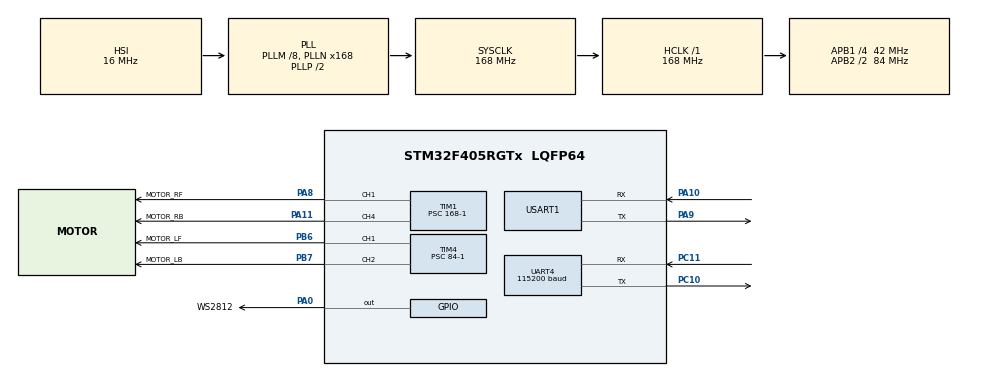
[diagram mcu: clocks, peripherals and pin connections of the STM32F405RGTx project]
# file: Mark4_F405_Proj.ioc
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Dma.Request0=USART1_RX
Dma.Request1=UART4_RX
Dma.UART4_RX.1.Direction=DMA_PERIPH_TO_MEMORY
Dma.UART4_RX.1.FIFOMode=DMA_FIFOMODE_DISABLE
Dma.UART4_RX.1.Instance=DMA1_Stream2
Dma.UART4_RX.1.MemDataAlignment=DMA_MDATAALIGN_BYTE
Dma.UART4_RX.1.MemInc=DMA_MINC_ENABLE
Dma.UART4_RX.1.Mode=DMA_NORMAL
Dma.UART4_RX.1.PeriphDataAlignment=DMA_PDATAALIGN_BYTE
Dma.UART4_RX.1.PeriphInc=DMA_PINC_DISABLE
Dma.UART4_RX.1.Priority=DMA_PRIORITY_LOW
Dma.USART1_RX.0.Direction=DMA_PERIPH_TO_MEMORY
Dma.USART1_RX.0.FIFOMode=DMA_FIFOMODE_DISABLE
Dma.USART1_RX.0.Instance=DMA2_Stream2
Dma.USART1_RX.0.MemDataAlignment=DMA_MDATAALIGN_BYTE
Dma.USART1_RX.0.MemInc=DMA_MINC_ENABLE
Dma.USART1_RX.0.Mode=DMA_NORMAL
Dma.USART1_RX.0.PeriphDataAlignment=DMA_PDATAALIGN_BYTE
Dma.USART1_RX.0.PeriphInc=DMA_PINC_DISABLE
Dma.USART1_RX.0.Priority=DMA_PRIORITY_LOW
Mcu.Family=STM32F4
Mcu.Name=STM32F405RGTx
Mcu.Package=LQFP64
NVIC.DMA1_Stream2_IRQn=true\:0\:0\:false\:false\:true\:false\:true\:true
NVIC.DMA2_Stream2_IRQn=true\:0\:0\:false\:false\:true\:false\:true\:true
NVIC.PriorityGroup=NVIC_PRIORITYGROUP_4
NVIC.TIM3_IRQn=true\:0\:0\:false\:false\:true\:true\:true\:true
NVIC.UART4_IRQn=true\:1\:0\:true\:false\:true\:true\:true\:true
NVIC.USART1_IRQn=true\:2\:0\:true\:false\:true\:true\:true\:true
PA0-WKUP.GPIO_Label=WS2812
PA0-WKUP.GPIO_Speed=GPIO_SPEED_FREQ_HIGH
PA0-WKUP.Signal=GPIO_Output
PA10.Mode=Asynchronous
PA10.Signal=USART1_RX
PA11.GPIO_Label=MOTOR_RB
PA11.Signal=S_TIM1_CH4
PA13.Mode=Serial_Wire
PA13.Signal=SYS_JTMS-SWDIO
PA14.Mode=Serial_Wire
PA14.Signal=SYS_JTCK-SWCLK
PA8.GPIO_Label=MOTOR_RF
PA8.Signal=S_TIM1_CH1
PA9.Mode=Asynchronous
PA9.Signal=USART1_TX
PB6.GPIO_Label=MOTOR_LF
PB6.Signal=S_TIM4_CH1
PB7.GPIO_Label=MOTOR_LB
PB7.Signal=S_TIM4_CH2
PC10.Mode=Asynchronous
PC10.Signal=UART4_TX
PC11.Mode=Asynchronous
PC11.Signal=UART4_RX
PH0-OSC_IN.Mode=HSE-External-Oscillator
PH0-OSC_IN.Signal=RCC_OSC_IN
PH1-OSC_OUT.Mode=HSE-External-Oscillator
PH1-OSC_OUT.Signal=RCC_OSC_OUT
ProjectManager.HeapSize=0x200
ProjectManager.StackSize=0x400
ProjectManager.TargetToolchain=CMake
RCC.48MHZClocksFreq_Value=84000000
RCC.AHBFreq_Value=168000000
RCC.APB1CLKDivider=RCC_HCLK_DIV4
RCC.APB1Freq_Value=42000000
RCC.APB1TimFreq_Value=84000000
RCC.APB2CLKDivider=RCC_HCLK_DIV2
RCC.APB2Freq_Value=84000000
RCC.APB2TimFreq_Value=168000000
RCC.CortexFreq_Value=168000000
RCC.HCLKFreq_Value=168000000
RCC.HSE_VALUE=12000000
RCC.HSI_VALUE=16000000
RCC.LSE_VALUE=32768
RCC.PLLM=8
RCC.PLLN=168
RCC.SYSCLKFreq_VALUE=168000000
RCC.SYSCLKSource=RCC_SYSCLKSOURCE_PLLCLK
RCC.VCOOutputFreq_Value=336000000
SH.S_TIM1_CH1.0=TIM1_CH1,PWM Generation1 CH1
SH.S_TIM1_CH4.0=TIM1_CH4,PWM Generation4 CH4
SH.S_TIM4_CH1.0=TIM4_CH1,PWM Generation1 CH1
SH.S_TIM4_CH2.0=TIM4_CH2,PWM Generation2 CH2
TIM1.AutoReloadPreload=TIM_AUTORELOAD_PRELOAD_ENABLE
TIM1.Channel-PWM\ Generation1\ CH1=TIM_CHANNEL_1
TIM1.Channel-PWM\ Generation4\ CH4=TIM_CHANNEL_4
TIM1.Period=20000-1
TIM1.Prescaler=168-1
TIM3.Period=9
TIM3.Prescaler=8399
TIM4.AutoReloadPreload=TIM_AUTORELOAD_PRELOAD_ENABLE
TIM4.Channel-PWM\ Generation1\ CH1=TIM_CHANNEL_1
TIM4.Channel-PWM\ Generation2\ CH2=TIM_CHANNEL_2
TIM4.Period=20000-1
TIM4.Prescaler=84-1
UART4.BaudRate=115200
UART4.VirtualMode=Asynchronous
USART1.VirtualMode=VM_ASYNC
VP_TIM1_VS_ClockSourceINT.Mode=Internal
VP_TIM3_VS_ClockSourceINT.Mode=Internal
VP_TIM4_VS_ClockSourceINT.Mode=Internal
board=custom

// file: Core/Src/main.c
/* USER CODE BEGIN Header */
/**
  ******************************************************************************
  * @file           : main.c
  * @brief          : Main program body
  ******************************************************************************
  * @attention
  *
  * Copyright (c) 2025 STMicroelectronics.
  * All rights reserved.
  *
  * This software is licensed under terms that can be found in the LICENSE file
  * in the root directory of this software component.
  * If no LICENSE file comes with this software, it is provided AS-IS.
  *
  ******************************************************************************
  */
/* USER CODE END Header */
#include "main.h"
#include "dma.h"
#include "tim.h"
#include "usart.h"
#include "gpio.h"

void SystemClock_Config(void);

int main(void)
{

  /* MCU Configuration--------------------------------------------------------*/

  /* Reset of all peripherals, Initializes the Flash interface and the Systick. */
  HAL_Init();

  /* Configure the system clock */
  SystemClock_Config();

  /* Initialize all configured peripherals */
  MX_GPIO_Init();
  MX_DMA_Init();
  MX_USART1_UART_Init();
  MX_UART4_Init();
  MX_TIM3_Init();
  MX_TIM1_Init();
  MX_TIM4_Init();
  /* USER CODE BEGIN 2 */

  HAL_TIM_PWM_Start(&htim1, TIM_CHANNEL_1); // 启动TIM1 CH1
  HAL_TIM_PWM_Start(&htim1, TIM_CHANNEL_4); // 启动TIM1 CH4
  HAL_TIM_PWM_Start(&htim4, TIM_CHANNEL_1); // 启动TIM4 CH1
  HAL_TIM_PWM_Start(&htim4, TIM_CHANNEL_2); // 启动TIM4 CH2

  init_drone_pids(&Drone_Pid);
  BT_Parser_Init();

  // WS2812_Init();
  // char* str = "hello\n";
  // HAL_UART_Transmit(&huart1, str, 6, 0xffff);

  /* USER CODE END 2 */

  /* Infinite loop */
  /* USER CODE BEGIN WHILE */
  while (1)
  {

    // HAL_Delay(1000);

    /* USER CODE END WHILE */

  }
}

void SystemClock_Config(void)
{
  RCC_OscInitTypeDef RCC_OscInitStruct = {0};
  RCC_ClkInitTypeDef RCC_ClkInitStruct = {0};

  /** Configure the main internal regulator output voltage
  */
  __HAL_RCC_PWR_CLK_ENABLE();
  __HAL_PWR_VOLTAGESCALING_CONFIG(PWR_REGULATOR_VOLTAGE_SCALE1);

  /** Initializes the RCC Oscillators according to the specified parameters
  * in the RCC_OscInitTypeDef structure.
  */
  RCC_OscInitStruct.OscillatorType = RCC_OSCILLATORTYPE_HSI;
  RCC_OscInitStruct.HSIState = RCC_HSI_ON;
  RCC_OscInitStruct.HSICalibrationValue = RCC_HSICALIBRATION_DEFAULT;
  RCC_OscInitStruct.PLL.PLLState = RCC_PLL_ON;
  RCC_OscInitStruct.PLL.PLLSource = RCC_PLLSOURCE_HSI;
  RCC_OscInitStruct.PLL.PLLM = 8;
  RCC_OscInitStruct.PLL.PLLN = 168;
  RCC_OscInitStruct.PLL.PLLP = RCC_PLLP_DIV2;
  RCC_OscInitStruct.PLL.PLLQ = 4;
  if (HAL_RCC_OscConfig(&RCC_OscInitStruct) != HAL_OK)
  {
    Error_Handler();
  }

  /** Initializes the CPU, AHB and APB buses clocks
  */
  RCC_ClkInitStruct.ClockType = RCC_CLOCKTYPE_HCLK|RCC_CLOCKTYPE_SYSCLK
                              |RCC_CLOCKTYPE_PCLK1|RCC_CLOCKTYPE_PCLK2;
  RCC_ClkInitStruct.SYSCLKSource = RCC_SYSCLKSOURCE_PLLCLK;
  RCC_ClkInitStruct.AHBCLKDivider = RCC_SYSCLK_DIV1;
  RCC_ClkInitStruct.APB1CLKDivider = RCC_HCLK_DIV4;
  RCC_ClkInitStruct.APB2CLKDivider = RCC_HCLK_DIV2;

  if (HAL_RCC_ClockConfig(&RCC_ClkInitStruct, FLASH_LATENCY_5) != HAL_OK)
  {
    Error_Handler();
  }
}

void Error_Handler(void)
{
  __disable_irq();
  while (1)
  {
  }
}
